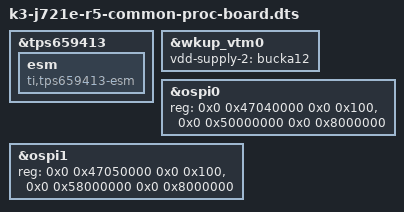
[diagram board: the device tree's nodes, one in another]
// SPDX-License-Identifier: GPL-2.0
/*
 * Copyright (C) 2019 Texas Instruments Incorporated - https://www.ti.com/
 */

/dts-v1/;

#include "k3-j721e-common-proc-board.dts"
#include "k3-j721e-ddr-evm-lp4-4266.dtsi"
#include "k3-j721e-ddr.dtsi"
#include "k3-j721e-common-proc-board-u-boot.dtsi"

#include "k3-j721e-r5.dtsi"

&tps659413 {
	esm: esm {
		compatible = "ti,tps659413-esm";
		bootph-pre-ram;
	};
};

&wkup_vtm0 {
	vdd-supply-2 = <&bucka12>;
	bootph-pre-ram;
};

&ospi0 {
	/* Address change for data region (32-bit) */
	reg = <0x0 0x47040000 0x0 0x100>,
	      <0x0 0x50000000 0x0 0x8000000>;
};

&ospi1 {
	/* Address change for data region (32-bit) */
	reg = <0x0 0x47050000 0x0 0x100>,
	      <0x0 0x58000000 0x0 0x8000000>;
};
